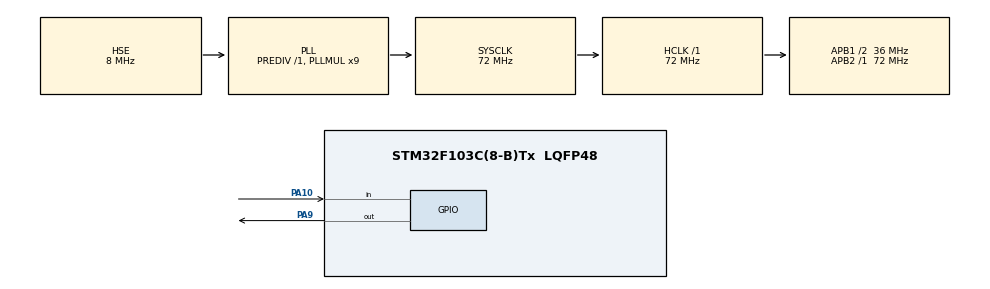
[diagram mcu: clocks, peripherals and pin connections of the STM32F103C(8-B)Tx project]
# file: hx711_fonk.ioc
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Mcu.Family=STM32F1
Mcu.Name=STM32F103C(8-B)Tx
Mcu.Package=LQFP48
NVIC.PriorityGroup=NVIC_PRIORITYGROUP_4
PA10.Signal=GPIO_Input
PA13.Mode=Serial_Wire
PA13.Signal=SYS_JTMS-SWDIO
PA14.Mode=Serial_Wire
PA14.Signal=SYS_JTCK-SWCLK
PA9.GPIO_Speed=GPIO_SPEED_FREQ_HIGH
PA9.PinState=GPIO_PIN_SET
PA9.Signal=GPIO_Output
PD0-OSC_IN.Mode=HSE-External-Oscillator
PD0-OSC_IN.Signal=RCC_OSC_IN
PD1-OSC_OUT.Mode=HSE-External-Oscillator
PD1-OSC_OUT.Signal=RCC_OSC_OUT
ProjectManager.HeapSize=0x200
ProjectManager.StackSize=0x400
ProjectManager.TargetToolchain=STM32CubeIDE
RCC.AHBFreq_Value=72000000
RCC.APB1CLKDivider=RCC_HCLK_DIV2
RCC.APB1Freq_Value=36000000
RCC.APB1TimFreq_Value=72000000
RCC.APB2Freq_Value=72000000
RCC.APB2TimFreq_Value=72000000
RCC.HCLKFreq_Value=72000000
RCC.PLLMUL=RCC_PLL_MUL9
RCC.PLLSourceVirtual=RCC_PLLSOURCE_HSE
RCC.SYSCLKFreq_VALUE=72000000
RCC.SYSCLKSource=RCC_SYSCLKSOURCE_PLLCLK
RCC.USBFreq_Value=72000000
board=custom

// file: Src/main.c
/* USER CODE BEGIN Header */
/**
  ******************************************************************************
  * @file           : main.c
  * @brief          : Main program body
  ******************************************************************************
  * @attention
  *
  * <h2><center>&copy; Copyright (c) 2019 STMicroelectronics.
  * All rights reserved.</center></h2>
  *
  * This software component is licensed by ST under BSD 3-Clause license,
  * the "License"; You may not use this file except in compliance with the
  * License. You may obtain a copy of the License at:
  *                        opensource.org/licenses/BSD-3-Clause
  *
  ******************************************************************************
  */
/* USER CODE END Header */

#include "main.h"

/* USER CODE BEGIN Includes */
#include "dwt_delay.h"
/* USER CODE END Includes */

/* USER CODE BEGIN PV */
uint32_t Hx_Value =0;
uint32_t Hx_Value1 =0;
uint32_t Hx_Value2 =0;
float Hx_Value3 = 0;
uint32_t Real_value =0;
/* USER CODE END PV */

void SystemClock_Config(void);
static void MX_GPIO_Init(void);
/* USER CODE BEGIN PFP */
uint32_t Hx_SingleRead_Value(int Gain);
uint32_t Hx_AvgRead_Value( int Gain, int times );
uint32_t Hx_Get_Value(int Gain,int times,float Scale);
/* USER CODE END PFP */

int main(void)
{

  /* MCU Configuration--------------------------------------------------------*/

  /* Reset of all peripherals, Initializes the Flash interface and the Systick. */
  HAL_Init();

  /* Configure the system clock */
  SystemClock_Config();

  /* Initialize all configured peripherals */
  MX_GPIO_Init();
  /* USER CODE BEGIN 2 */
  int32_t zero_value=Hx_AvgRead_Value(1,10);

  /* USER CODE END 2 */

  /* Infinite loop */
  while (1)
  {

	  Hx_Value1=Hx_AvgRead_Value(1,10);
	  Hx_Value2=Hx_Value1-zero_value;
	  Hx_Value3= Hx_Value2/2000;
  }
}

void SystemClock_Config(void)
{
  RCC_OscInitTypeDef RCC_OscInitStruct = {0};
  RCC_ClkInitTypeDef RCC_ClkInitStruct = {0};

  /** Initializes the CPU, AHB and APB busses clocks
  */
  RCC_OscInitStruct.OscillatorType = RCC_OSCILLATORTYPE_HSE;
  RCC_OscInitStruct.HSEState = RCC_HSE_ON;
  RCC_OscInitStruct.HSEPredivValue = RCC_HSE_PREDIV_DIV1;
  RCC_OscInitStruct.HSIState = RCC_HSI_ON;
  RCC_OscInitStruct.PLL.PLLState = RCC_PLL_ON;
  RCC_OscInitStruct.PLL.PLLSource = RCC_PLLSOURCE_HSE;
  RCC_OscInitStruct.PLL.PLLMUL = RCC_PLL_MUL9;
  if (HAL_RCC_OscConfig(&RCC_OscInitStruct) != HAL_OK)
  {
    Error_Handler();
  }
  /** Initializes the CPU, AHB and APB busses clocks
  */
  RCC_ClkInitStruct.ClockType = RCC_CLOCKTYPE_HCLK|RCC_CLOCKTYPE_SYSCLK
                              |RCC_CLOCKTYPE_PCLK1|RCC_CLOCKTYPE_PCLK2;
  RCC_ClkInitStruct.SYSCLKSource = RCC_SYSCLKSOURCE_PLLCLK;
  RCC_ClkInitStruct.AHBCLKDivider = RCC_SYSCLK_DIV1;
  RCC_ClkInitStruct.APB1CLKDivider = RCC_HCLK_DIV2;
  RCC_ClkInitStruct.APB2CLKDivider = RCC_HCLK_DIV1;

  if (HAL_RCC_ClockConfig(&RCC_ClkInitStruct, FLASH_LATENCY_2) != HAL_OK)
  {
    Error_Handler();
  }
}

static void MX_GPIO_Init(void)
{
  GPIO_InitTypeDef GPIO_InitStruct = {0};

  /* GPIO Ports Clock Enable */
  __HAL_RCC_GPIOD_CLK_ENABLE();
  __HAL_RCC_GPIOA_CLK_ENABLE();

  /*Configure GPIO pin Output Level */
  HAL_GPIO_WritePin(GPIOA, GPIO_PIN_9, GPIO_PIN_SET);

  /*Configure GPIO pin : PA9 */
  GPIO_InitStruct.Pin = GPIO_PIN_9;
  GPIO_InitStruct.Mode = GPIO_MODE_OUTPUT_PP;
  GPIO_InitStruct.Pull = GPIO_NOPULL;
  GPIO_InitStruct.Speed = GPIO_SPEED_FREQ_LOW;
  HAL_GPIO_Init(GPIOA, &GPIO_InitStruct);

  /*Configure GPIO pin : PA10 */
  GPIO_InitStruct.Pin = GPIO_PIN_10;
  GPIO_InitStruct.Mode = GPIO_MODE_INPUT;
  GPIO_InitStruct.Pull = GPIO_NOPULL;
  HAL_GPIO_Init(GPIOA, &GPIO_InitStruct);

}

/* USER CODE BEGIN 4 */
uint32_t Hx_SingleRead_Value(int Gain)
	{
		uint32_t value1=0;

		for(int i =0;i<24; i++){
			HAL_GPIO_WritePin(GPIOA , GPIO_PIN_9 , GPIO_PIN_SET);
			value1=value1 << 1;
			DWT_Delay(1);
			HAL_GPIO_WritePin(GPIOA , GPIO_PIN_9 , GPIO_PIN_RESET);
			if(HAL_GPIO_ReadPin(GPIOA , GPIO_PIN_10)==1) {
				value1++;
				DWT_Delay(1);
			}

		}

		for(int g =0; g<Gain ; g++)
				{
						HAL_GPIO_WritePin(GPIOA , GPIO_PIN_9 , GPIO_PIN_SET);
						DWT_Delay(1);
						HAL_GPIO_WritePin(GPIOA , GPIO_PIN_9 , GPIO_PIN_RESET);
				}

				value1= value1 ^ 0x800000;
				return value1;

	}
	uint32_t Hx_AvgRead_Value( int Gain, int times)
			{
				uint32_t sum_data = 0;
				for(int i=0;i<times ; i++){

					sum_data+= Hx_SingleRead_Value(Gain);

				}
				return sum_data/times ;
			}
	uint32_t Hx_Get_Value(int Gain,int times,float Scale)
					{
					uint32_t Read_Kg=0;
						Read_Kg= Hx_AvgRead_Value(Gain,times)/ Scale;

					return Read_Kg;
					}

/* USER CODE END 4 */

void Error_Handler(void)
{
}

/************************ (C) COPYRIGHT STMicroelectronics *****END OF FILE****/
